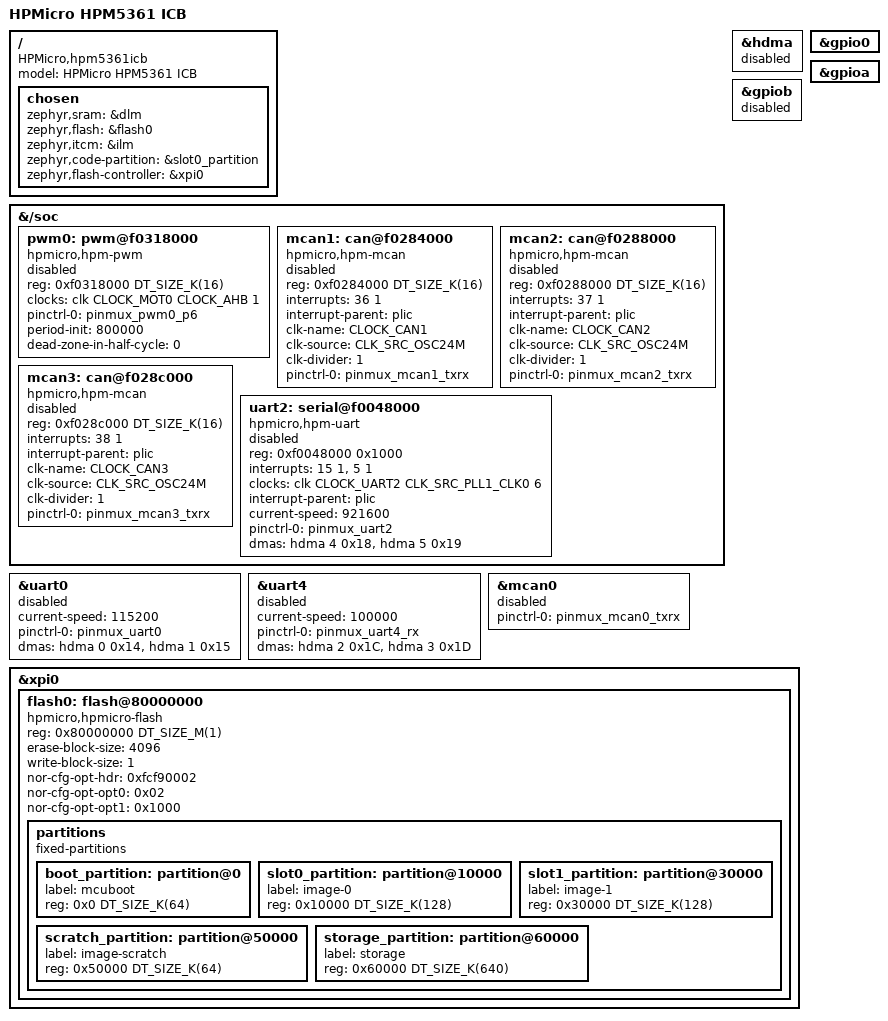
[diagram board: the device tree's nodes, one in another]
/*
 * Copyright 2025 HPMicro
 * SPDX-License-Identifier: Apache-2.0
 */

/dts-v1/;

#include <zephyr/dt-bindings/gpio/gpio.h>
#include <dt-bindings/clock/hpm5361-clocks.h>
#include <hpmicro/hpm5361.dtsi>
#include "hpm5361icb-pinctrl.dtsi"

/ {
	model = "HPMicro HPM5361 ICB";
	compatible = "HPMicro,hpm5361icb";

	chosen {
		zephyr,sram = &dlm;
		zephyr,flash = &flash0;
		zephyr,itcm = &ilm;
		zephyr,code-partition = &slot0_partition;
		zephyr,flash-controller = &xpi0;
	};

};

&{/soc} {
	pwm0: pwm@f0318000 {
		compatible = "hpmicro,hpm-pwm";
		reg = <0xf0318000 DT_SIZE_K(16)>;
		clocks = <&clk CLOCK_MOT0 CLOCK_AHB 1>;
		pinctrl-0 = <&pinmux_pwm0_p6>;
		pinctrl-names = "default";
		period-init = <800000>;
		dead-zone-in-half-cycle = <0>;
		status = "disabled";
		#pwm-cells = <3>;
	};

	/* SoC dtsi（hpm53xx.dtsi）只声明到 mcan0 / uart0..4，这里补齐板上实际用到的：
	 *   mcan1 0xF0284000 IRQ36 · mcan2 0xF0288000 IRQ37 · mcan3 0xF028C000 IRQ38
	 *   uart2 0xF0048000 IRQ15(UART2) + IRQ5(idletimer)
	 * MCAN 时钟用 OSC24M/1：24MHz ÷ 1Mbps = 24 tq，位时序精确（PLL1 无法整除）。
	 */
	mcan1: can@f0284000 {
		compatible = "hpmicro,hpm-mcan";
		reg = <0xf0284000 DT_SIZE_K(16)>;
		interrupts = <36 1>;
		interrupt-parent = <&plic>;
		clk-name = <CLOCK_CAN1>;
		clk-source = <CLK_SRC_OSC24M>;
		clk-divider = <1>;
		status = "disabled";
	};

	mcan2: can@f0288000 {
		compatible = "hpmicro,hpm-mcan";
		reg = <0xf0288000 DT_SIZE_K(16)>;
		interrupts = <37 1>;
		interrupt-parent = <&plic>;
		clk-name = <CLOCK_CAN2>;
		clk-source = <CLK_SRC_OSC24M>;
		clk-divider = <1>;
		status = "disabled";
	};

	mcan3: can@f028c000 {
		compatible = "hpmicro,hpm-mcan";
		reg = <0xf028c000 DT_SIZE_K(16)>;
		interrupts = <38 1>;
		interrupt-parent = <&plic>;
		clk-name = <CLOCK_CAN3>;
		clk-source = <CLK_SRC_OSC24M>;
		clk-divider = <1>;
		status = "disabled";
	};

	uart2: serial@f0048000 {
		compatible = "hpmicro,hpm-uart";
		reg = <0xf0048000 0x1000>;
		interrupts = <15 1>, <5 1>;
		interrupt-names = "uart", "idletimer";
		clocks = <&clk CLOCK_UART2 CLK_SRC_PLL1_CLK0 6>;
		interrupt-parent = <&plic>;
		status = "disabled";
	};
};

&uart0 {
	status = "disabled";
	current-speed = <115200>;
	pinctrl-0 = <&pinmux_uart0>;
	pinctrl-names = "default";
	dmas = <&hdma 0 0x14>, <&hdma 1 0x15>;
	dma-names = "rx", "tx";
};

&uart4 {
	status = "disabled";
	current-speed = <100000>;
	pinctrl-0 = <&pinmux_uart4_rx>;
	pinctrl-names = "default";
	dmas = <&hdma 2 0x1C>, <&hdma 3 0x1D>;
	dma-names = "rx", "tx";
};

&hdma {
	status = "disabled";
};

&gpio0 {
	status = "okay";
};

&gpioa {
	status = "okay";
};

&gpiob {
	status = "disabled";
};

&mcan0 {
	status = "disabled";
	pinctrl-0 = <&pinmux_mcan0_txrx>;
	pinctrl-names = "default";
};

&mcan1 {
	status = "disabled";
	pinctrl-0 = <&pinmux_mcan1_txrx>;
	pinctrl-names = "default";
};

&mcan2 {
	status = "disabled";
	pinctrl-0 = <&pinmux_mcan2_txrx>;
	pinctrl-names = "default";
};

&mcan3 {
	status = "disabled";
	pinctrl-0 = <&pinmux_mcan3_txrx>;
	pinctrl-names = "default";
};

/* 板载 "UART2"/H4 连接器（console）：H4.3 = 板侧 RXD，H4.4 = 板侧 TXD */
&uart2 {
	status = "disabled";
	current-speed = <921600>;
	pinctrl-0 = <&pinmux_uart2>;
	pinctrl-names = "default";
	/* DMA 通道 4/5（原本是 uart3 那一对，uart3 已停用不再启用）。
	 * 通道号只是 HDMA 的槽位，0x18/0x19 = UART2_RX/TX（DMAMUX 源）必须跟外设对应。
	 * 这样 0/1 留给 uart0，通道分配不再重复。 */
	dmas = <&hdma 4 0x18>, <&hdma 5 0x19>;
	dma-names = "rx", "tx";
};

&xpi0 {
	status = "okay";

	flash0: flash@80000000 {
		compatible = "hpmicro,hpmicro-flash", "soc-nv-flash";
		reg = <0x80000000 DT_SIZE_M(1)>;
		status = "okay";
		erase-block-size = <4096>;
		write-block-size = <1>;
		nor-cfg-opt-hdr = <0xfcf90002>;
		nor-cfg-opt-opt0 = <0x02>;
		nor-cfg-opt-opt1 = <0x1000>;

		partitions {
			compatible = "fixed-partitions";
			#address-cells = <1>;
			#size-cells = <1>;

			boot_partition: partition@0 {
				label = "mcuboot";
				reg = <0x0 DT_SIZE_K(64)>;
			};

			slot0_partition: partition@10000 {
				label = "image-0";
				reg = <0x10000 DT_SIZE_K(128)>;
			};

			slot1_partition: partition@30000 {
				label = "image-1";
				reg = <0x30000 DT_SIZE_K(128)>;
			};

			scratch_partition: partition@50000 {
				label = "image-scratch";
				reg = <0x50000 DT_SIZE_K(64)>;
			};

			storage_partition: partition@60000 {
				label = "storage";
				reg = <0x60000 DT_SIZE_K(640)>;
			};
		};
	};
};
